# ATSAMA5D27 register map
Vendor: Microchip Technology Inc.; File version: 1.0
CPU: CA5 r0p1, little endian, no MPU, no FPU, 4 interrupt priority bits
Address unit: 32 bits
Registers are 32-bit, read-write, reset 0x0 unless marked. A register's access mark holds for its fields unless they carry their own. Offsets are from the block's base; [hi:lo] are bit positions; {n}, {i} and the like mark numbered series; 'fields as' and 'values as' point back to an identical list.

## TC0 — Timer Counter
Base 0xF800C000
Same registers: TC1 0xF8010000
0x00 BCR wo — Block Control Register
  [0] SYNC rw — Synchro Command
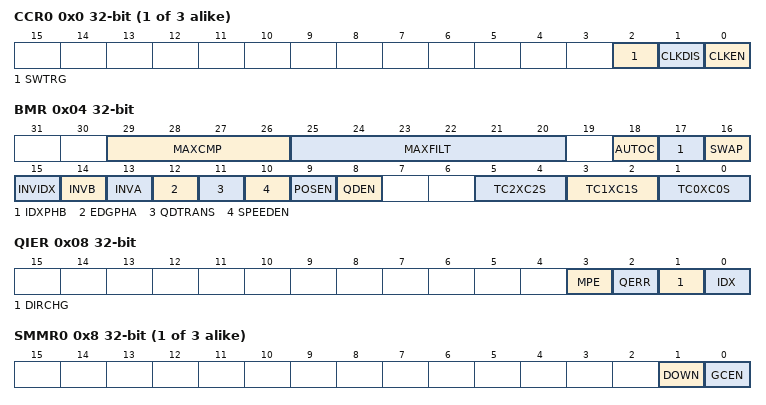
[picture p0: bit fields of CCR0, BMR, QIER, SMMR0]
{0x0+0x40*i} CCR{i} (i=0..2) — Channel Control Register.
  [2] SWTRG — Software Trigger Command.
  [1] CLKDIS — Counter Clock Disable Command.
  [0] CLKEN — Counter Clock Enable Command.
0x04 BMR — Block Mode Register
  [29:26] MAXCMP — Maximum Consecutive Missing Pulses
  [25:20] MAXFILT — Maximum Filter
  [18] AUTOC — AutoCorrection of missing pulses
    0=DISABLED (The detection and autocorrection function is disabled.); 1=ENABLED (The detection and autocorrection function is enabled.)
  [17] IDXPHB — Index Pin is PHB Pin
  [16] SWAP — Swap PHA and PHB
  [15] INVIDX — Inverted Index
  [14] INVB — Inverted PHB
  [13] INVA — Inverted PHA
  [12] EDGPHA — Edge on PHA Count Mode
  [11] QDTRANS — Quadrature Decoding Transparent
  [10] SPEEDEN — Speed Enabled
  [9] POSEN — Position Enabled
  [8] QDEN — Quadrature Decoder Enabled
  [5:4] TC2XC2S — External Clock Signal 2 Selection
    0=TCLK2 (Signal connected to XC2: TCLK2); 2=TIOA0 (Signal connected to XC2: TIOA0); 3=TIOA1 (Signal connected to XC2: TIOA1)
  [3:2] TC1XC1S — External Clock Signal 1 Selection
    0=TCLK1 (Signal connected to XC1: TCLK1); 2=TIOA0 (Signal connected to XC1: TIOA0); 3=TIOA2 (Signal connected to XC1: TIOA2)
  [1:0] TC0XC0S — External Clock Signal 0 Selection
    0=TCLK0 (Signal connected to XC0: TCLK0); 2=TIOA1 (Signal connected to XC0: TIOA1); 3=TIOA2 (Signal connected to XC0: TIOA2)
{0x4+0x40*i} CMR{i} (i=0..2) — Channel Mode Register.
0x08 QIER wo — QDEC Interrupt Enable Register
  [3] MPE rw — Consecutive Missing Pulse Error
  [2] QERR rw — Quadrature Error
  [1] DIRCHG rw — Direction Change
  [0] IDX rw — Index
{0x8+0x40*i} SMMR{i} (i=0..2) — Stepper Motor Mode Register.
  [1] DOWN — Down Count
  [0] GCEN — Gray Count Enable
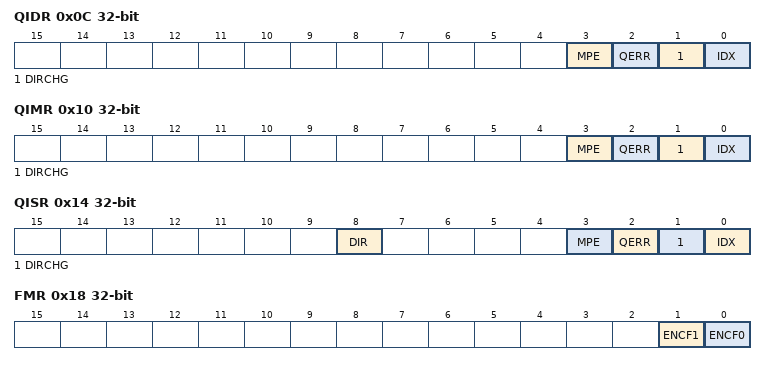
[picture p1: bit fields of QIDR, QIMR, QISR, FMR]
0x0C QIDR wo — QDEC Interrupt Disable Register
  fields as QIER
{0xC+0x40*i} RAB{i} (i=0..2) — Register A or B.
0x10 QIMR ro — QDEC Interrupt Mask Register
  fields as QIER
{0x10+0x40*i} CV{i} (i=0..2) — Counter Value.
0x14 QISR ro — QDEC Interrupt Status Register
  [8] DIR rw — Direction
  [3] MPE rw — Consecutive Missing Pulse Error
  [2] QERR rw — Quadrature Error
  [1] DIRCHG rw — Direction Change
  [0] IDX rw — Index
0x14 RA0 — Register A.
0x18 FMR — Fault Mode Register
  [1] ENCF1 — Enable Compare Fault Channel 1
  [0] ENCF0 — Enable Compare Fault Channel 0
0x18 RB0 — Register B.
0x1C RC0 — Register C.
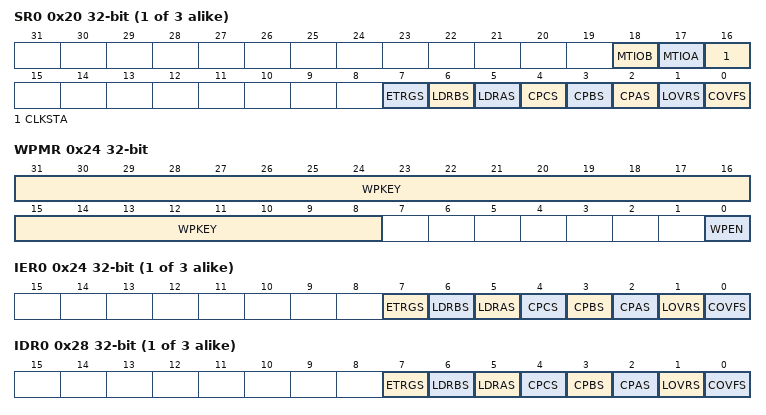
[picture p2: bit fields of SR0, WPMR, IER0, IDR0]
{0x20+0x40*i} SR{i} (i=0..2) — Interrupt Status Register.
  [18] MTIOB — TIOBx Mirror
  [17] MTIOA — TIOAx Mirror
  [16] CLKSTA — Clock Enabling Status
  [7] ETRGS — External Trigger Status (cleared on read)
  [6] LDRBS — RB Loading Status (cleared on read)
  [5] LDRAS — RA Loading Status (cleared on read)
  [4] CPCS — RC Compare Status (cleared on read)
  [3] CPBS — RB Compare Status (cleared on read)
  [2] CPAS — RA Compare Status (cleared on read)
  [1] LOVRS — Load Overrun Status (cleared on read)
  [0] COVFS — Counter Overflow Status (cleared on read)
0x24 WPMR — Write Protection Mode Register
  [31:8] WPKEY — Write Protection Key
    0x54494D=PASSWD (Writing any other value in this field aborts the write operation of the WPEN bit.Always reads as 0.)
  [0] WPEN — Write Protection Enable
{0x24+0x40*i} IER{i} (i=0..2) — Interrupt Enable Register
  [7] ETRGS — External Trigger
  [6] LDRBS — RB Loading
  [5] LDRAS — RA Loading
  [4] CPCS — RC Compare
  [3] CPBS — RB Compare
  [2] CPAS — RA Compare
  [1] LOVRS — Load Overrun
  [0] COVFS — Counter Overflow
{0x28+0x40*i} IDR{i} (i=0..2) — Interrupt Disable Register
  fields as IER0
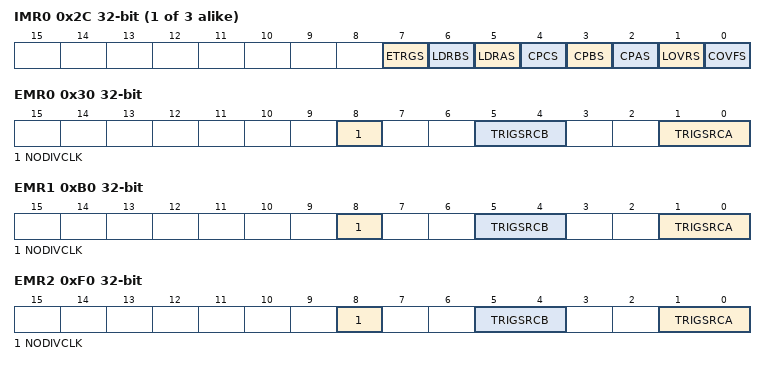
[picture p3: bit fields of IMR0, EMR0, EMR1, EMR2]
{0x2C+0x40*i} IMR{i} (i=0..2) — Interrupt Mask Register
  fields as IER0
0x30 EMR0 — Extended Mode Register.
  [8] NODIVCLK — No Divided Clock.
  [5:4] TRIGSRCB — Trigger Source for Input B.
  [1:0] TRIGSRCA — Trigger Source for Input A.
0x54 RA1 — Register A.
0x58 RB1 — Register B.
0x5C RC1 — Register C.
0x84 RA2 — Register A.
0x88 RB2 — Register B.
0x8C RC2 — Register C.
0xB0 EMR1 — Extended Mode Register.
  fields as EMR0
0xF0 EMR2 — Extended Mode Register.
  fields as EMR0
